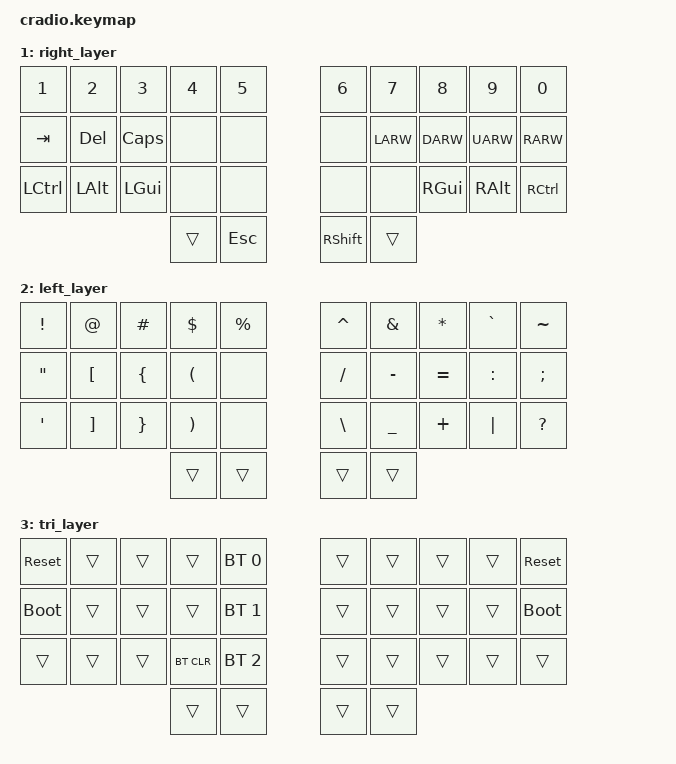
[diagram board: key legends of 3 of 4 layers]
// Copyright (c) 2022 The ZMK Contributors
// SPDX-License-Identifier: MIT

#include <behaviors.dtsi>
#include <dt-bindings/zmk/keys.h>
#include <dt-bindings/zmk/bt.h>

// Home row mods macro
#define HRML(k1,k2,k3,k4) &ht LSHFT k1  &ht LALT k2  &ht LCTRL k3  &ht LGUI k4

/ {
    behaviors {
        ht: hold_tap {
            label = "hold_tap";
            compatible = "zmk,behavior-hold-tap";
            #binding-cells = <2>;
            flavor = "tap-preferred";
            tapping-term-ms = <220>;
            quick-tap-ms = <150>;
            require-prior-idle-ms = <100>;
            bindings = <&kp>, <&kp>;
        };
    };

    conditional_layers {
        compatible = "zmk,conditional-layers";
        tri_layer {
            if-layers = <1 2>;
            then-layer = <3>;
        };
    };

    keymap {
        compatible = "zmk,keymap";
        default_layer {
            bindings = <
        //╭──────────┬──────────┬──────────┬──────────┬──────────╮   ╭──────────┬──────────┬──────────┬──────────┬──────────╮
        //│  Q       │  W       │  E       │  R       │  T       │   │  Y       │  U       │  I       │  O       │  P       │
            &kp Q      &kp W      &kp E      &kp R      &kp T          &kp Y      &kp U      &kp I      &kp O      &kp P
        //├──────────┼──────────┼──────────┼──────────┼──────────┤   ├──────────┼──────────┼──────────┼──────────┼──────────┤
        //│  A       │  S       │  D       │  F       │  G       │   │  H       │  J       │  K       │  L       │ ; :      │
            HRML(A,        S,         D,         F)     &kp G          &kp H      &kp J      &kp K      &kp L    &kp SEMI
        //├──────────┼──────────┼──────────┼──────────┼──────────┤   ├──────────┼──────────┼──────────┼──────────┼──────────┤
        //│  Z       │  X       │  C       │  V       │  B       │   │  N       │  M       │ , <      │ . >      │          │
            &kp Z      &kp X      &kp C      &kp V      &kp B          &kp N      &kp M      &kp COMMA  &kp DOT    &kp ENTER
        //╰──────────┴──────────┴──────────┼──────────┼──────────┤   ├──────────┼──────────┼──────────┴──────────┴──────────╯
                                            &lt 2 TAB  &kp LSHFT     &ht SPACE LGUI  &lt 1 BSPC
        //                                 ╰──────────┴──────────╯   ╰──────────┴──────────╯
            >;
        };

        right_layer {
            bindings = <
        //╭──────────┬──────────┬──────────┬──────────┬──────────╮   ╭──────────┬──────────┬──────────┬──────────┬──────────╮
        //│ 1        │  2       │  3       │  4       │  5       │   │ 6        │ 7        │ 8        │ 9        │   0      │
            &kp N1    &kp N2     &kp N3     &kp N4     &kp N5          &kp N6     &kp N7     &kp N8     &kp N9      &kp N0
        //├──────────┼──────────┼──────────┼──────────┼──────────┤   ├──────────┼──────────┼──────────┼──────────┼──────────┤
        //│ TAB      │ DELETE   │ CapsLock │          │          |   |          │ LEFT     │ DOWN     │ UP       │ RIGHT    │
            &kp TAB     &kp DEL   &kp CAPS     &none     &none          &none    &kp LARW   &kp DARW   &kp UARW   &kp RARW 
        //├──────────┼──────────┼──────────┼──────────┼──────────┤   ├──────────┼──────────┼──────────┼──────────┼──────────┤
        //│          │          │          │          │          │   │          │          │          │          │          │
            &kp LCTRL  &kp LALT  &kp LGUI   &none      &none            &none     &none     &kp RGUI   &kp RALT  &kp RCTRL 
        //╰──────────┴──────────┴──────────┼──────────┼──────────┤   ├──────────┼──────────┼──────────┴──────────┴──────────╯
                                             &trans     &kp ESC        &kp RSHFT     &trans
        //                                 ╰──────────┴──────────╯   ╰──────────┴──────────╯
            >;
        };

        left_layer {
            bindings = <
        //╭──────────┬──────────┬──────────┬──────────┬──────────╮   ╭──────────┬──────────┬──────────┬──────────┬──────────╮
        //│  !       │  @       │  #       │  $       │  %       │   │  ^       │  &       │  *       │  `       │  ~       │
            &kp EXCL   &kp AT     &kp HASH   &kp DLLR   &kp PRCNT      &kp CARET  &kp AMPS   &kp ASTRK  &kp GRAVE   &kp TILDE
        //├──────────┼──────────┼──────────┼──────────┼──────────┤   ├──────────┼──────────┼──────────┼──────────┼──────────┤
        //│  "       │  [       │          │          │          │   │   /      │  -       │  =       │     :    │  ;       │
            &kp DQT    &kp LBKT   &kp LBRC   &kp LPAR   &none         &kp FSLH   &kp MINUS  &kp EQUAL  &kp COLON   &kp SEMI
        //├──────────┼──────────┼──────────┼──────────┼──────────┤   ├──────────┼──────────┼──────────┼──────────┼──────────┤
        //│  '       │  ]       │          │          │          │   │    \     │  _       │  +       │  │       │   ?      │
            &kp SQT     &kp RBKT   &kp RBRC   &kp RPAR   &none         &kp BSLH   &kp UNDER  &kp PLUS   &kp PIPE  &kp QMARK
        //╰──────────┴──────────┴──────────┼──────────┼──────────┤   ├──────────┼──────────┼──────────┴──────────┴──────────╯
                                             &trans     &trans         &trans     &trans
        //                                 ╰──────────┴──────────╯   ╰──────────┴──────────╯
            >;
        };

        tri_layer {
            bindings = <
        //╭──────────┬──────────┬──────────┬──────────┬──────────╮   ╭──────────┬──────────┬──────────┬──────────┬──────────╮
        //│ RESET    │          │          │          │PROFILE 0 │   │          │          │          │          │  RESET   │
           &sys_reset  &trans     &trans     &trans    &bt BT_SEL 0    &trans     &trans     &trans     &trans    &sys_reset
        //├──────────┼──────────┼──────────┼──────────┼──────────┤   ├──────────┼──────────┼──────────┼──────────┼──────────┤
        //│BOOTLOADER│          │          │          │PROFILE 1 │   │          │          │          │          │BOOTLOADER│
          &bootloader  &trans     &trans     &trans    &bt BT_SEL 1    &trans     &trans     &trans     &trans    &bootloader
        //├──────────┼──────────┼──────────┼──────────┼──────────┤   ├──────────┼──────────┼──────────┼──────────┼──────────┤
        //│          │          │          │ CLEAR BT │PROFILE 2 │   │          │          │          │          │          │
            &trans     &trans     &trans    &bt BT_CLR &bt BT_SEL 2    &trans     &trans     &trans     &trans     &trans
        //╰──────────┴──────────┴──────────┼──────────┼──────────┤   ├──────────┼──────────┼──────────┴──────────┴──────────╯
                                             &trans     &trans         &trans     &trans
        //                                 ╰──────────┴──────────╯   ╰──────────┴──────────╯
            >;
        };
    };
};
